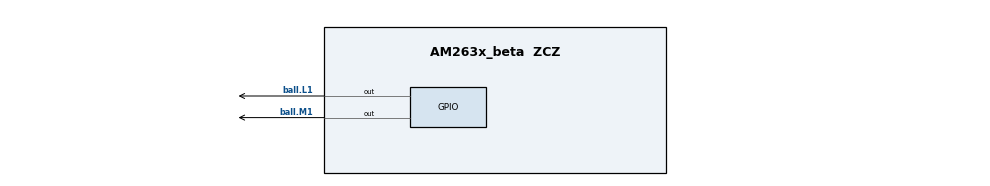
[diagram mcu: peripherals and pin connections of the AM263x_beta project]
/**
 * @cliArgs --device "AM263x_beta" --package "ZCZ" --part "AM263x" --context "r5fss0-0" --product "MCU_PLUS_SDK@07.03.01"
 * @versions {"tool":"1.13.0+2553"}
 */

/**
 * Import the modules used in this configuration.
 */
const adc         = scripting.addModule("/drivers/adc/adc", {}, false);
const adc1        = adc.addInstance();
const adc2        = adc.addInstance();
const gpio        = scripting.addModule("/drivers/gpio/gpio", {}, false);
const gpio1       = gpio.addInstance();
const gpio2       = gpio.addInstance();
const debug_log   = scripting.addModule("/kernel/dpl/debug_log");
const mpu_armv7   = scripting.addModule("/kernel/dpl/mpu_armv7", {}, false);
const mpu_armv71  = mpu_armv7.addInstance();
const mpu_armv72  = mpu_armv7.addInstance();
const mpu_armv73  = mpu_armv7.addInstance();
const mpu_armv74  = mpu_armv7.addInstance();
const input_xbar  = scripting.addModule("/xbar/input_xbar/input_xbar", {}, false);
const input_xbar1 = input_xbar.addInstance();
const int_xbar    = scripting.addModule("/xbar/int_xbar/int_xbar", {}, false);
const int_xbar1   = int_xbar.addInstance();
const int_xbar2   = int_xbar.addInstance();

/**
 * Write custom configuration values to the imported modules.
 */
adc1.$name                 = "CONFIG_ADC1";
adc1.enableInterrupt1      = true;
adc1.enableInterrupt2      = true;
adc1.interrupt1SOCSource   = "ADC_SOC_NUMBER15";
adc1.interrupt2SOCSource   = "ADC_SOC_NUMBER7";
adc1.enableConverter       = true;
adc1.soc0Trigger           = "ADC_TRIGGER_INPUT_XBAR_OUT5";
adc1.soc0InterruptTrigger  = "ADC_INT_SOC_TRIGGER_ADCINT1";
adc1.soc1Trigger           = "ADC_TRIGGER_INPUT_XBAR_OUT5";
adc1.soc1InterruptTrigger  = "ADC_INT_SOC_TRIGGER_ADCINT1";
adc1.soc2Trigger           = "ADC_TRIGGER_INPUT_XBAR_OUT5";
adc1.soc2InterruptTrigger  = "ADC_INT_SOC_TRIGGER_ADCINT1";
adc1.soc3Trigger           = "ADC_TRIGGER_INPUT_XBAR_OUT5";
adc1.soc3InterruptTrigger  = "ADC_INT_SOC_TRIGGER_ADCINT1";
adc1.soc4Trigger           = "ADC_TRIGGER_INPUT_XBAR_OUT5";
adc1.soc4InterruptTrigger  = "ADC_INT_SOC_TRIGGER_ADCINT1";
adc1.soc5Trigger           = "ADC_TRIGGER_INPUT_XBAR_OUT5";
adc1.soc5InterruptTrigger  = "ADC_INT_SOC_TRIGGER_ADCINT1";
adc1.soc6Trigger           = "ADC_TRIGGER_INPUT_XBAR_OUT5";
adc1.soc6InterruptTrigger  = "ADC_INT_SOC_TRIGGER_ADCINT1";
adc1.soc7Trigger           = "ADC_TRIGGER_INPUT_XBAR_OUT5";
adc1.soc7InterruptTrigger  = "ADC_INT_SOC_TRIGGER_ADCINT1";
adc1.soc8Trigger           = "ADC_TRIGGER_INPUT_XBAR_OUT5";
adc1.soc8InterruptTrigger  = "ADC_INT_SOC_TRIGGER_ADCINT1";
adc1.soc9Trigger           = "ADC_TRIGGER_INPUT_XBAR_OUT5";
adc1.soc9InterruptTrigger  = "ADC_INT_SOC_TRIGGER_ADCINT1";
adc1.soc10Trigger          = "ADC_TRIGGER_INPUT_XBAR_OUT5";
adc1.soc10InterruptTrigger = "ADC_INT_SOC_TRIGGER_ADCINT1";
adc1.soc11Trigger          = "ADC_TRIGGER_INPUT_XBAR_OUT5";
adc1.soc11InterruptTrigger = "ADC_INT_SOC_TRIGGER_ADCINT1";
adc1.soc12Trigger          = "ADC_TRIGGER_INPUT_XBAR_OUT5";
adc1.soc12InterruptTrigger = "ADC_INT_SOC_TRIGGER_ADCINT1";
adc1.soc13Trigger          = "ADC_TRIGGER_INPUT_XBAR_OUT5";
adc1.soc13InterruptTrigger = "ADC_INT_SOC_TRIGGER_ADCINT1";
adc1.soc14Trigger          = "ADC_TRIGGER_INPUT_XBAR_OUT5";
adc1.soc14InterruptTrigger = "ADC_INT_SOC_TRIGGER_ADCINT1";
adc1.soc15Trigger          = "ADC_TRIGGER_INPUT_XBAR_OUT5";
adc1.soc15InterruptTrigger = "ADC_INT_SOC_TRIGGER_ADCINT1";
adc1.soc1Channel           = "ADC_CH_ADCIN1";
adc1.soc3Channel           = "ADC_CH_ADCIN1";
adc1.soc5Channel           = "ADC_CH_ADCIN1";
adc1.soc7Channel           = "ADC_CH_ADCIN1";
adc1.soc9Channel           = "ADC_CH_ADCIN1";
adc1.soc11Channel          = "ADC_CH_ADCIN1";
adc1.soc13Channel          = "ADC_CH_ADCIN1";
adc1.soc15Channel          = "ADC_CH_ADCIN1";
adc1.soc0SampleWindow      = 17;
adc1.soc1SampleWindow      = 17;
adc1.soc2SampleWindow      = 17;
adc1.soc3SampleWindow      = 17;
adc1.soc4SampleWindow      = 17;
adc1.soc5SampleWindow      = 17;
adc1.soc6SampleWindow      = 17;
adc1.soc7SampleWindow      = 17;
adc1.soc8SampleWindow      = 17;
adc1.soc9SampleWindow      = 17;
adc1.soc10SampleWindow     = 17;
adc1.soc11SampleWindow     = 17;
adc1.soc12SampleWindow     = 17;
adc1.soc13SampleWindow     = 17;
adc1.soc14SampleWindow     = 17;
adc1.soc15SampleWindow     = 17;
adc1.adcClockPrescaler     = "ADC_CLK_DIV_4_0";
adc1.ADC.$assign           = "ADC1";

adc2.$name                 = "CONFIG_ADC2";
adc2.enableInterrupt1      = true;
adc2.interrupt1SOCSource   = "ADC_SOC_NUMBER15";
adc2.enableConverter       = true;
adc2.soc0Trigger           = "ADC_TRIGGER_INPUT_XBAR_OUT5";
adc2.soc0InterruptTrigger  = "ADC_INT_SOC_TRIGGER_ADCINT1";
adc2.soc1Trigger           = "ADC_TRIGGER_INPUT_XBAR_OUT5";
adc2.soc1InterruptTrigger  = "ADC_INT_SOC_TRIGGER_ADCINT1";
adc2.soc2Trigger           = "ADC_TRIGGER_INPUT_XBAR_OUT5";
adc2.soc2InterruptTrigger  = "ADC_INT_SOC_TRIGGER_ADCINT1";
adc2.soc3Trigger           = "ADC_TRIGGER_INPUT_XBAR_OUT5";
adc2.soc3InterruptTrigger  = "ADC_INT_SOC_TRIGGER_ADCINT1";
adc2.soc4Trigger           = "ADC_TRIGGER_INPUT_XBAR_OUT5";
adc2.soc4InterruptTrigger  = "ADC_INT_SOC_TRIGGER_ADCINT1";
adc2.soc5Trigger           = "ADC_TRIGGER_INPUT_XBAR_OUT5";
adc2.soc5InterruptTrigger  = "ADC_INT_SOC_TRIGGER_ADCINT1";
adc2.soc6Trigger           = "ADC_TRIGGER_INPUT_XBAR_OUT5";
adc2.soc6InterruptTrigger  = "ADC_INT_SOC_TRIGGER_ADCINT1";
adc2.soc7Trigger           = "ADC_TRIGGER_INPUT_XBAR_OUT5";
adc2.soc7InterruptTrigger  = "ADC_INT_SOC_TRIGGER_ADCINT1";
adc2.soc8Trigger           = "ADC_TRIGGER_INPUT_XBAR_OUT5";
adc2.soc8InterruptTrigger  = "ADC_INT_SOC_TRIGGER_ADCINT1";
adc2.soc9Trigger           = "ADC_TRIGGER_INPUT_XBAR_OUT5";
adc2.soc9InterruptTrigger  = "ADC_INT_SOC_TRIGGER_ADCINT1";
adc2.soc10Trigger          = "ADC_TRIGGER_INPUT_XBAR_OUT5";
adc2.soc10InterruptTrigger = "ADC_INT_SOC_TRIGGER_ADCINT1";
adc2.soc11Trigger          = "ADC_TRIGGER_INPUT_XBAR_OUT5";
adc2.soc11InterruptTrigger = "ADC_INT_SOC_TRIGGER_ADCINT1";
adc2.soc12Trigger          = "ADC_TRIGGER_INPUT_XBAR_OUT5";
adc2.soc12InterruptTrigger = "ADC_INT_SOC_TRIGGER_ADCINT1";
adc2.soc13Trigger          = "ADC_TRIGGER_INPUT_XBAR_OUT5";
adc2.soc13InterruptTrigger = "ADC_INT_SOC_TRIGGER_ADCINT1";
adc2.soc14Trigger          = "ADC_TRIGGER_INPUT_XBAR_OUT5";
adc2.soc14InterruptTrigger = "ADC_INT_SOC_TRIGGER_ADCINT1";
adc2.soc15Trigger          = "ADC_TRIGGER_INPUT_XBAR_OUT5";
adc2.soc15InterruptTrigger = "ADC_INT_SOC_TRIGGER_ADCINT1";
adc2.soc1Channel           = "ADC_CH_ADCIN1";
adc2.soc3Channel           = "ADC_CH_ADCIN1";
adc2.soc5Channel           = "ADC_CH_ADCIN1";
adc2.soc7Channel           = "ADC_CH_ADCIN1";
adc2.soc9Channel           = "ADC_CH_ADCIN1";
adc2.soc11Channel          = "ADC_CH_ADCIN1";
adc2.soc13Channel          = "ADC_CH_ADCIN1";
adc2.soc15Channel          = "ADC_CH_ADCIN1";
adc2.soc0SampleWindow      = 17;
adc2.soc1SampleWindow      = 17;
adc2.soc2SampleWindow      = 17;
adc2.soc3SampleWindow      = 17;
adc2.soc4SampleWindow      = 17;
adc2.soc5SampleWindow      = 17;
adc2.soc6SampleWindow      = 17;
adc2.soc7SampleWindow      = 17;
adc2.soc8SampleWindow      = 17;
adc2.soc9SampleWindow      = 17;
adc2.soc10SampleWindow     = 17;
adc2.soc11SampleWindow     = 17;
adc2.soc12SampleWindow     = 17;
adc2.soc13SampleWindow     = 17;
adc2.soc14SampleWindow     = 17;
adc2.soc15SampleWindow     = 17;
adc2.adcClockPrescaler     = "ADC_CLK_DIV_4_0";
adc2.ADC.$assign           = "ADC2";

gpio1.$name                = "CONFIG_GPIO_INPUT";
gpio1.GPIO.$assign         = "GPIO0";
gpio1.GPIO.gpioPin.$assign = "ball.M1";

gpio2.pinDir               = "OUTPUT";
gpio2.$name                = "CONFIG_GPIO_OUTPUT";
gpio2.GPIO.gpioPin.$assign = "ball.L1";

debug_log.enableUartLog            = true;
debug_log.uartLog.$name            = "CONFIG_UART0";
debug_log.uartLog.UART.RXD.$assign = "ball.A7";
debug_log.uartLog.UART.TXD.$assign = "ball.A6";

mpu_armv71.$name             = "CONFIG_MPU_REGION0";
mpu_armv71.size              = 31;
mpu_armv71.attributes        = "Device";
mpu_armv71.accessPermissions = "Supervisor RD+WR, User RD";
mpu_armv71.allowExecute      = false;

mpu_armv72.$name             = "CONFIG_MPU_REGION1";
mpu_armv72.size              = 15;
mpu_armv72.accessPermissions = "Supervisor RD+WR, User RD";

mpu_armv73.$name             = "CONFIG_MPU_REGION2";
mpu_armv73.baseAddr          = 0x80000;
mpu_armv73.size              = 15;
mpu_armv73.accessPermissions = "Supervisor RD+WR, User RD";

mpu_armv74.$name             = "CONFIG_MPU_REGION3";
mpu_armv74.accessPermissions = "Supervisor RD+WR, User RD";
mpu_armv74.baseAddr          = 0x70000000;
mpu_armv74.size              = 21;

input_xbar1.$name      = "CONFIG_INPUT_XBAR0";
input_xbar1.instance   = "INPUT_XBAR_5";
input_xbar1.xbarOutput = "GPIO7";

int_xbar1.$name      = "CONFIG_INT_XBAR0";
int_xbar1.xbarOutput = ["ADC1_INT2"];

int_xbar2.$name      = "CONFIG_INT_XBAR1";
int_xbar2.xbarOutput = ["ADC1_INT1"];
int_xbar2.instance   = "INT_XBAR_1";

/**
 * Pinmux solution for unlocked pins/peripherals. This ensures that minor changes to the automatic solver in a future
 * version of the tool will not impact the pinmux you originally saw.  These lines can be completely deleted in order to
 * re-solve from scratch.
 */
adc1.ADC.AIN0.$suggestSolution          = "ball.T11";
adc1.ADC.AIN1.$suggestSolution          = "ball.U11";
adc1.ADC.AIN2.$suggestSolution          = "ball.T12";
adc1.ADC.AIN3.$suggestSolution          = "ball.V12";
adc1.ADC.AIN4.$suggestSolution          = "ball.U12";
adc1.ADC.AIN5.$suggestSolution          = "ball.R12";
adc2.ADC.AIN0.$suggestSolution          = "ball.R10";
adc2.ADC.AIN1.$suggestSolution          = "ball.T10";
adc2.ADC.AIN2.$suggestSolution          = "ball.U10";
adc2.ADC.AIN3.$suggestSolution          = "ball.T9";
adc2.ADC.AIN4.$suggestSolution          = "ball.V9";
adc2.ADC.AIN5.$suggestSolution          = "ball.T8";
gpio2.GPIO.$suggestSolution             = "GPIO0";
debug_log.uartLog.UART.$suggestSolution = "UART0";
